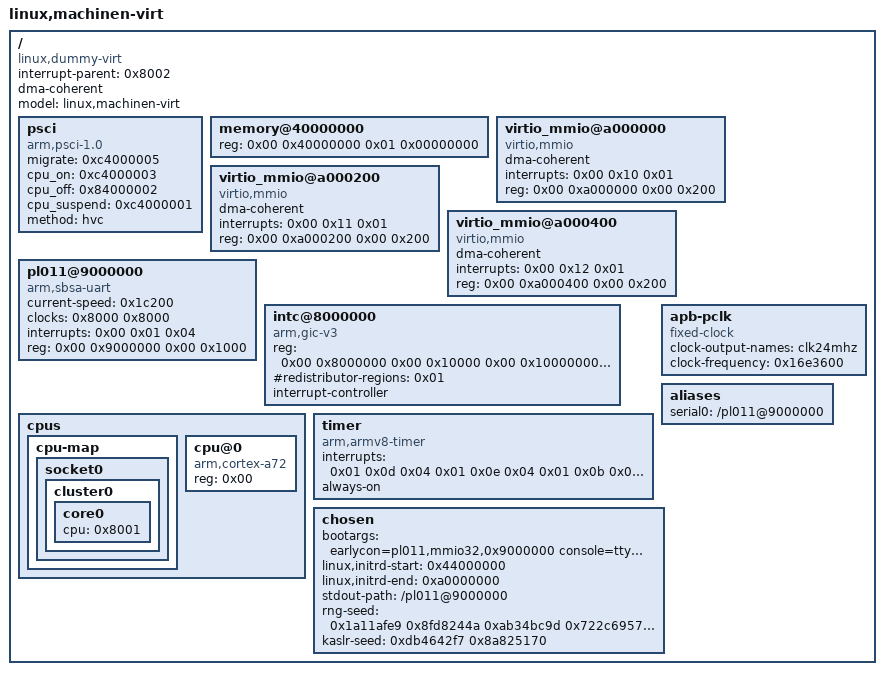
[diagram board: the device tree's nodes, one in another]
/dts-v1/;

// Minimal arm64 "virt"-style device tree — trimmed for fast boot.
//
// What stays in is what the guest kernel + our VMM actually touch:
//   * the GIC v3 (interrupt controller — required)
//   * PL011 UART at 0x9000000 (console)
//   * three virtio-mmio slots (net / blk / vsock at 0x0a000000+i*0x200)
//   * CPU, timer, psci, apb-pclk
//
// Nodes we *used* to carry via the QEMU virt reference DTS and have
// now dropped for sub-second-spawn work (#50): `pcie`, `pl031` rtc,
// `pmu`, `flash`, `fw-cfg`, `platform-bus`, `gpio-keys`/`pl061`, the
// GIC ITS, and 29 unused virtio_mmio slots. Each of these made the
// kernel spend time probing things we never use.

/ {
	interrupt-parent = <0x8002>;
	dma-coherent;
	model = "linux,machinen-virt";
	#size-cells = <0x02>;
	#address-cells = <0x02>;
	compatible = "linux,dummy-virt";

	psci {
		migrate = <0xc4000005>;
		cpu_on = <0xc4000003>;
		cpu_off = <0x84000002>;
		cpu_suspend = <0xc4000001>;
		method = "hvc";
		compatible = "arm,psci-1.0", "arm,psci-0.2", "arm,psci";
	};

	memory@40000000 {
		reg = <0x00 0x40000000 0x01 0x00000000>;
		device_type = "memory";
	};

	virtio_mmio@a000000 {
		dma-coherent;
		interrupts = <0x00 0x10 0x01>;
		reg = <0x00 0xa000000 0x00 0x200>;
		compatible = "virtio,mmio";
	};

	virtio_mmio@a000200 {
		dma-coherent;
		interrupts = <0x00 0x11 0x01>;
		reg = <0x00 0xa000200 0x00 0x200>;
		compatible = "virtio,mmio";
	};

	virtio_mmio@a000400 {
		dma-coherent;
		interrupts = <0x00 0x12 0x01>;
		reg = <0x00 0xa000400 0x00 0x200>;
		compatible = "virtio,mmio";
	};

	pl011@9000000 {
		current-speed = <0x1c200>;  // 115200
		clock-names = "uartclk", "apb_pclk";
		clocks = <0x8000 0x8000>;
		interrupts = <0x00 0x01 0x04>;
		reg = <0x00 0x9000000 0x00 0x1000>;
		compatible = "arm,sbsa-uart";
	};

	intc@8000000 {
		phandle = <0x8002>;
		reg = <0x00 0x8000000 0x00 0x10000 0x00 0x10000000 0x00 0x2000000>;
		#redistributor-regions = <0x01>;
		compatible = "arm,gic-v3";
		ranges;
		#size-cells = <0x02>;
		#address-cells = <0x02>;
		interrupt-controller;
		#interrupt-cells = <0x03>;
	};

	cpus {
		#size-cells = <0x00>;
		#address-cells = <0x01>;

		cpu-map {
			socket0 {
				cluster0 {
					core0 {
						cpu = <0x8001>;
					};
				};
			};
		};

		cpu@0 {
			phandle = <0x8001>;
			reg = <0x00>;
			compatible = "arm,cortex-a72";
			device_type = "cpu";
		};
	};

	timer {
		interrupts = <0x01 0x0d 0x04 0x01 0x0e 0x04 0x01 0x0b 0x04 0x01 0x0a 0x04>;
		always-on;
		compatible = "arm,armv8-timer", "arm,armv7-timer";
	};

	apb-pclk {
		phandle = <0x8000>;
		clock-output-names = "clk24mhz";
		clock-frequency = <0x16e3600>;
		#clock-cells = <0x00>;
		compatible = "fixed-clock";
	};

	aliases {
		serial0 = "/pl011@9000000";
	};

	chosen {
		bootargs = "earlycon=pl011,mmio32,0x9000000 console=ttyAMA0 panic=1 loglevel=3 quiet";
		linux,initrd-start = <0x44000000>;
		linux,initrd-end = <0xa0000000>;
		stdout-path = "/pl011@9000000";
		rng-seed = <0x1a11afe9 0x8fd8244a 0xab34bc9d 0x722c6957 0xd0b2f2e0 0x82d58105 0x88b74715 0x107ef8a1>;
		kaslr-seed = <0xdb4642f7 0x8a825170>;
	};
};
